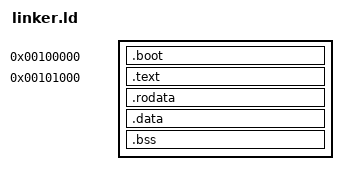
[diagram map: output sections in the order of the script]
OUTPUT_FORMAT(elf32-i386)

STARTUP_PHYSICAL_ADDRESS = 0x00100000;
KERNEL_PHYSICAL_ADDRESS  = 0x00101000;
KERNEL_VIRTUAL_ADDRESS   = 0xC0000000;

SECTIONS
{
	. = STARTUP_PHYSICAL_ADDRESS;

	.boot :
	{
		obj/init/startup.o
	}

	. = KERNEL_PHYSICAL_ADDRESS;
	. += KERNEL_VIRTUAL_ADDRESS;

	.text ALIGN(4K) : AT(ADDR(.text) - KERNEL_VIRTUAL_ADDRESS)
	{
		*(.text)
	}


	.rodata ALIGN(4K) : AT(ADDR(.rodata) - KERNEL_VIRTUAL_ADDRESS)
	{
		RODATA_BEGIN = .;
		*(.rodata)
	}


	.data ALIGN(4K) : AT(ADDR(.data) - KERNEL_VIRTUAL_ADDRESS)
	{
		DATA_BEGIN = .;
		*(.data)
	}

	.bss ALIGN(4K) : AT(ADDR(.bss) - KERNEL_VIRTUAL_ADDRESS)
	{
		BSS_SECTION_START = .;
		*(.bss)
		*(COMMON)
	}

	BSS_SECTION_END = .;
	KERNEL_VIRTUAL_ADDRESS_END = .;
}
